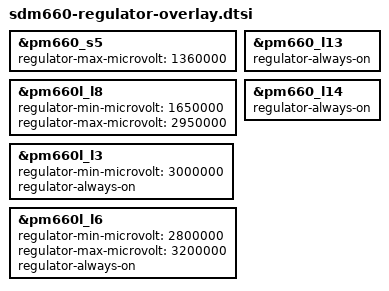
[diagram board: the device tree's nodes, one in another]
/* SPDX-License-Identifier: GPL-2.0 */

&pm660_s5 {
	regulator-max-microvolt = <1360000>;
};

&pm660l_l8 {
	regulator-min-microvolt = <1650000>;
	regulator-max-microvolt = <2950000>;
};

&pm660_l13 {
	regulator-always-on; /* ASUS BSP Always Enable 1.8V for BLSP ( NFC, ChargerIC, Power, Audio ) I2C */
};

&pm660_l14 {
	regulator-always-on; /* ASUS BSP Always Enable 1.8V for I2C & Sensors */
};

&pm660l_l3 {
	regulator-min-microvolt = <3000000>;
	regulator-always-on; /* ASUS BSP Always Enable 3V for ALS/PS Sensors */
};

&pm660l_l6 {
	regulator-min-microvolt = <2800000>;
	regulator-max-microvolt = <3200000>;
	regulator-always-on; /*ASUSBSP Eason enable 3V for RGB*/
};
